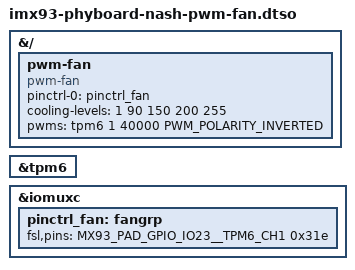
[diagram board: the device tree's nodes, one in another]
// SPDX-License-Identifier: (GPL-2.0+ OR MIT)
/*
 * Copyright (C) 2025 PHYTEC Messtechnik GmbH
 * Author: Andrej Picej <andrej.picej@norik.com>
 */

#include <dt-bindings/pwm/pwm.h>
#include "imx93-pinfunc.h"

/dts-v1/;
/plugin/;

&{/} {
	pwm-fan {
		compatible = "pwm-fan";
		#cooling-cells = <2>;
		pinctrl-names = "default";
		pinctrl-0 = <&pinctrl_fan>;
		cooling-levels = <1 90 150 200 255>;
		pwms = <&tpm6 1 40000 PWM_POLARITY_INVERTED>;
	};
};

&tpm6 {
	status = "okay";
};

&iomuxc {
	pinctrl_fan: fangrp {
		fsl,pins = <
			MX93_PAD_GPIO_IO23__TPM6_CH1		0x31e
		>;
	};
};
